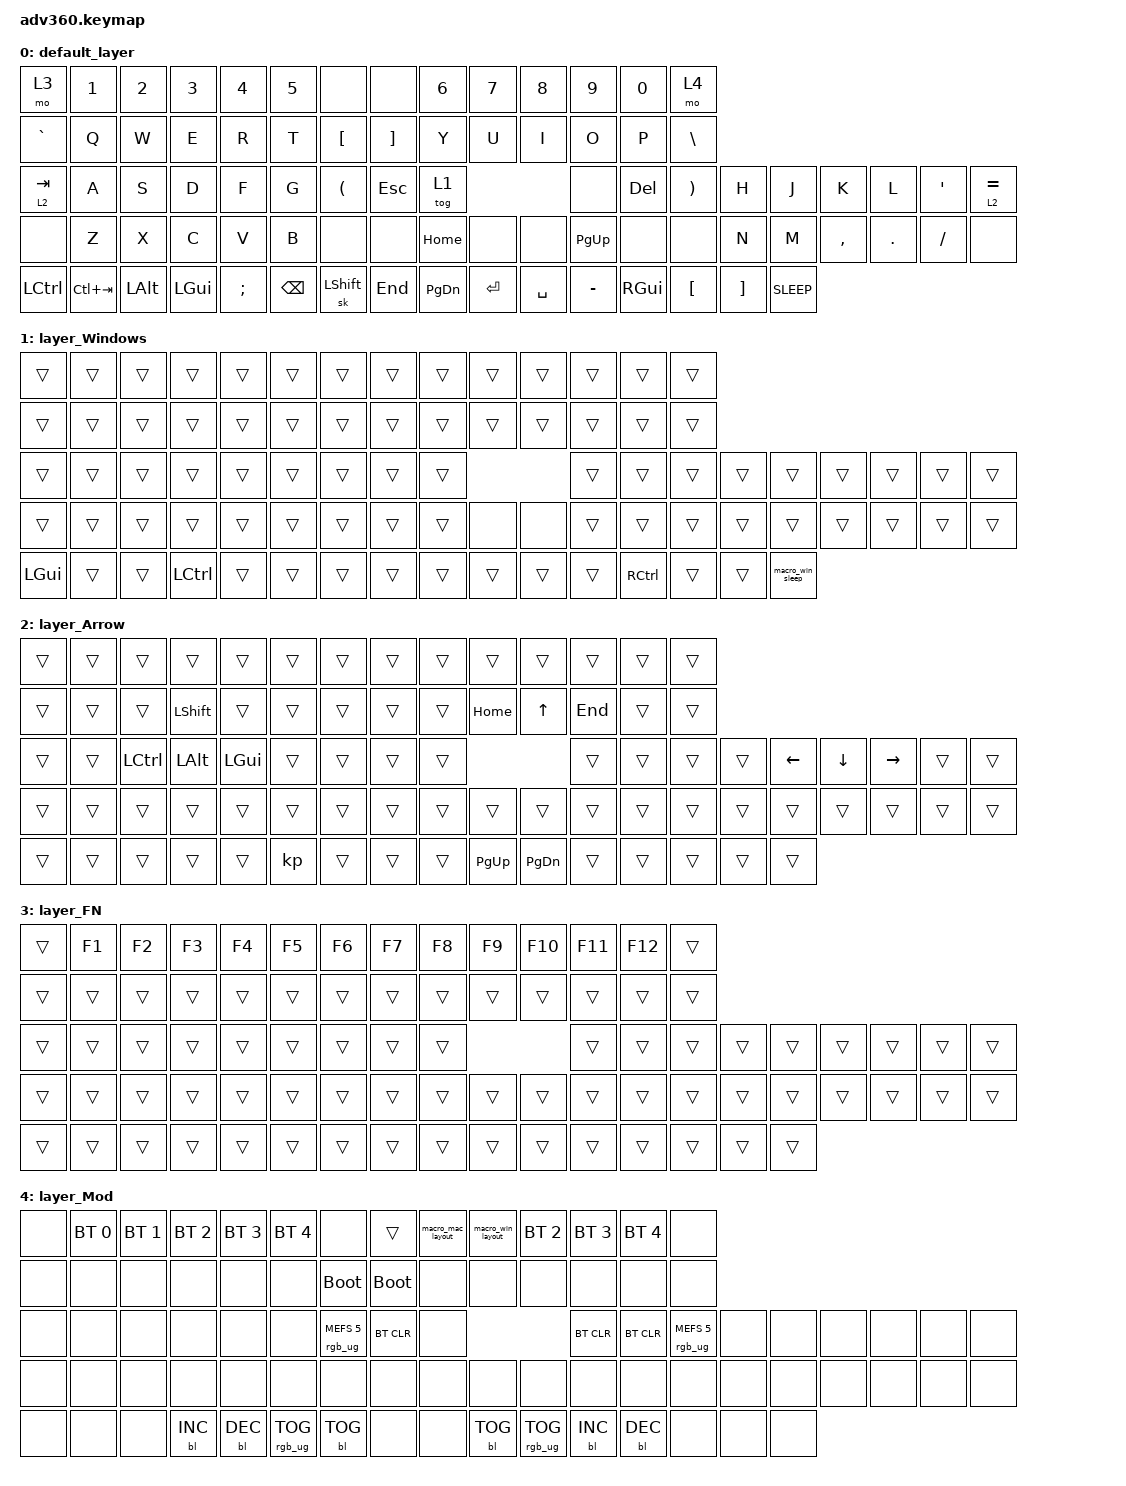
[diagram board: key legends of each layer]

/*
 * Copyright (c) 2020 The ZMK Contributors
 *
 * SPDX-License-Identifier: MIT
 */


/* THIS FILE WAS GENERATED!
 *
 * This file was generated automatically. You may or may not want to
 * edit it directly.
 */

#include <behaviors.dtsi>
#include <dt-bindings/zmk/keys.h>
#include <dt-bindings/zmk/bt.h>
#include <dt-bindings/zmk/rgb.h>
#include <dt-bindings/zmk/backlight.h>

/ {
  behaviors {
    #include "macros.dtsi"

    hm: homerow_mods {
        compatible = "zmk,behavior-hold-tap";
        label = "HOMEROW_MODS";
        #binding-cells = <2>;
        tapping-term-ms = <200>;
        quick_tap_ms = <175>;
        flavor = "tap-preferred";
        bindings = <&kp>, <&kp>;
    };
  };

    keymap {
        compatible = "zmk,keymap";


        default_layer {
            bindings = <
     &mo 3       &kp N1    &kp N2    &kp N3    &kp N4    &kp N5                 &none     &none     &kp N6     &kp N7     &kp N8     &kp N9    &kp N0     &mo 4
 &kp GRAVE        &kp Q     &kp W     &kp E     &kp R     &kp T              &kp LBKT  &kp RBKT      &kp Y      &kp U      &kp I      &kp O     &kp P  &kp BSLH
 &lt 2 TAB        &kp A     &kp S     &kp D     &kp F     &kp G              &kp LPAR   &kp ESC     &tog 1                            &none   &kp DEL  &kp RPAR     &kp H        &kp J      &kp K    &kp L  &kp SINGLE_QUOTE  &lt 2 EQUAL
     &none        &kp Z     &kp X     &kp C     &kp V     &kp B                 &none     &none   &kp HOME      &none      &none  &kp PG_UP     &none     &none     &kp N        &kp M  &kp COMMA  &kp DOT          &kp FSLH        &none
 &kp LCTRL  &kp LC(TAB)  &kp LALT  &kp LGUI  &kp SEMI  &kp BSPC            &sk LSHIFT   &kp END  &kp PG_DN  &kp ENTER  &kp SPACE  &kp MINUS  &kp RGUI  &kp LBKT  &kp RBKT  &kp C_SLEEP
            >;
        };

        layer_Windows {
            bindings = <
   &trans  &trans  &trans     &trans  &trans  &trans            &trans  &trans  &trans  &trans  &trans  &trans     &trans  &trans
   &trans  &trans  &trans     &trans  &trans  &trans            &trans  &trans  &trans  &trans  &trans  &trans     &trans  &trans
   &trans  &trans  &trans     &trans  &trans  &trans            &trans  &trans  &trans                  &trans     &trans  &trans  &trans            &trans  &trans  &trans  &trans  &trans
   &trans  &trans  &trans     &trans  &trans  &trans            &trans  &trans  &trans   &none   &none  &trans     &trans  &trans  &trans            &trans  &trans  &trans  &trans  &trans
 &kp LGUI  &trans  &trans  &kp LCTRL  &trans  &trans            &trans  &trans  &trans  &trans  &trans  &trans  &kp RCTRL  &trans  &trans  &macro_win_sleep
            >;
        };

        layer_Arrow {
            bindings = <
 &trans  &trans     &trans      &trans    &trans  &trans            &trans  &trans  &trans     &trans     &trans   &trans  &trans  &trans
 &trans  &trans     &trans  &kp LSHIFT    &trans  &trans            &trans  &trans  &trans   &kp HOME     &kp UP  &kp END  &trans  &trans
 &trans  &trans  &kp LCTRL    &kp LALT  &kp LGUI  &trans            &trans  &trans  &trans                         &trans  &trans  &trans  &trans  &kp LEFT  &kp DOWN  &kp RIGHT  &trans  &trans
 &trans  &trans     &trans      &trans    &trans  &trans            &trans  &trans  &trans     &trans     &trans   &trans  &trans  &trans  &trans    &trans    &trans     &trans  &trans  &trans
 &trans  &trans     &trans      &trans    &trans     &kp            &trans  &trans  &trans  &kp PG_UP  &kp PG_DN   &trans  &trans  &trans  &trans    &trans
            >;
        };

        layer_FN {
            bindings = <
 &trans  &kp F1  &kp F2  &kp F3  &kp F4  &kp F5            &kp F6  &kp F7  &kp F8  &kp F9  &kp F10  &kp F11  &kp F12  &trans
 &trans  &trans  &trans  &trans  &trans  &trans            &trans  &trans  &trans  &trans   &trans   &trans   &trans  &trans
 &trans  &trans  &trans  &trans  &trans  &trans            &trans  &trans  &trans                    &trans   &trans  &trans  &trans  &trans  &trans  &trans  &trans  &trans
 &trans  &trans  &trans  &trans  &trans  &trans            &trans  &trans  &trans  &trans   &trans   &trans   &trans  &trans  &trans  &trans  &trans  &trans  &trans  &trans
 &trans  &trans  &trans  &trans  &trans  &trans            &trans  &trans  &trans  &trans   &trans   &trans   &trans  &trans  &trans  &trans
            >;
        };

        layer_Mod {
            bindings = <
  &none  &bt BT_SEL 0  &bt BT_SEL 1  &bt BT_SEL 2  &bt BT_SEL 3     &bt BT_SEL 4                             &none       &trans  &macro_mac_layout  &macro_win_layout     &bt BT_SEL 2  &bt BT_SEL 3  &bt BT_SEL 4                   &none
  &none         &none         &none         &none         &none            &none                       &bootloader  &bootloader              &none              &none            &none         &none         &none                   &none
  &none         &none         &none         &none         &none            &none            &rgb_ug RGB_MEFS_CMD 5   &bt BT_CLR              &none                                        &bt BT_CLR    &bt BT_CLR  &rgb_ug RGB_MEFS_CMD 5   &none   &none   &none   &none   &none   &none
  &none         &none         &none         &none         &none            &none                             &none        &none              &none              &none            &none         &none         &none                   &none   &none   &none   &none   &none   &none   &none
  &none         &none         &none    &bl BL_INC    &bl BL_DEC  &rgb_ug RGB_TOG                        &bl BL_TOG        &none              &none         &bl BL_TOG  &rgb_ug RGB_TOG    &bl BL_INC    &bl BL_DEC                   &none   &none   &none
            >;
        };

    };
};
